# FSS0_FSAS_OTFA_REGS_0FC20000h register map
Vendor: Texas Instruments
Peripheral module from a debugger description file (folder AM275x).
Registers are 32-bit, read-write, reset 0x0 unless marked. A register's access mark holds for its fields unless they carry their own. Offsets are as the file gives them; lines under a group give offsets from that group; [hi:lo] are bit positions; {n}, {i} and the like mark numbered series; 'fields as' and 'values as' point back to an identical list; <NAME> marks a mode.

## fsas_otfa_regs
0x00 FSAS_OTFA_REGS_REVID ro reset 0x47500101 — Revision
  [31:0] REVID — REVID Reset Source: rst_modg_rst_n
0x04 FSAS_OTFA_REGS_SCFG reset 0x2 — SysConfig
  [1:0] IDLE_MODE — IDLE MODE Reset Source: rst_modg_rst_n
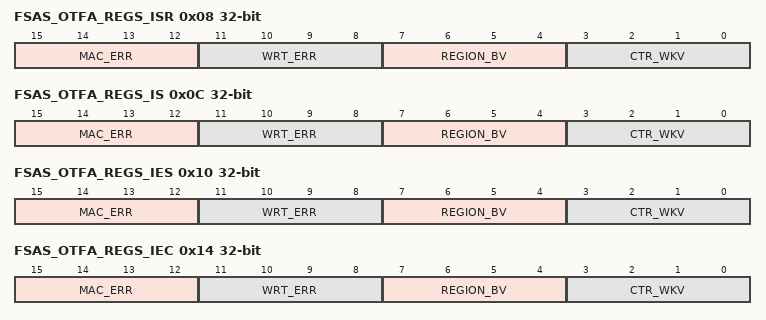
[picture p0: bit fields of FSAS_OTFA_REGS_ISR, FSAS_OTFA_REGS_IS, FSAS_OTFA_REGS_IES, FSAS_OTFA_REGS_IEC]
0x08 FSAS_OTFA_REGS_ISR — IRQSTATUS_RAW
  [15:12] MAC_ERR — MAC error Reset Source: rst_modg_rst_n
  [11:8] WRT_ERR — Write error Reset Source: rst_modg_rst_n
  [7:4] REGION_BV — Region overflow boundary event caused by a burst transaction crossed a start or end of a region Reset Source: rst_modg_rst_n
  [3:0] CTR_WKV — AES mode 0 enabled region violated Wrt Once Per Wrt Key rule Reset Source: rst_modg_rst_n
0x0C FSAS_OTFA_REGS_IS — IRQSTATUS
  fields as FSAS_OTFA_REGS_ISR
0x10 FSAS_OTFA_REGS_IES — IRQENABLE_SET
  fields as FSAS_OTFA_REGS_ISR
0x14 FSAS_OTFA_REGS_IEC — IRQENABLE_CLR
  fields as FSAS_OTFA_REGS_ISR
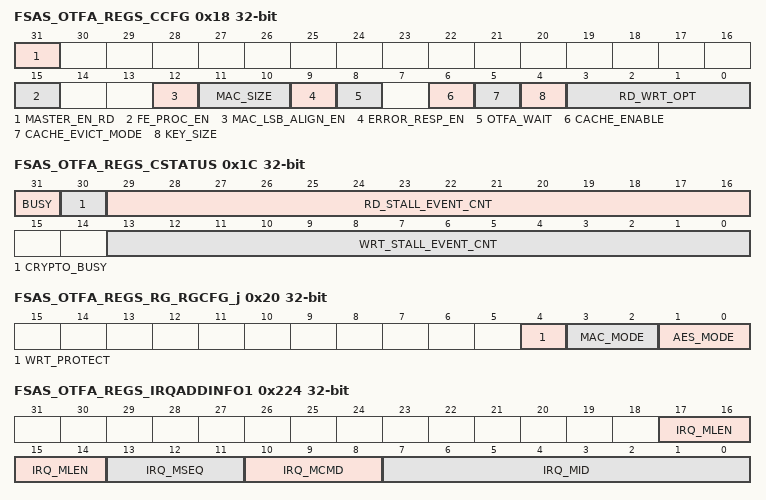
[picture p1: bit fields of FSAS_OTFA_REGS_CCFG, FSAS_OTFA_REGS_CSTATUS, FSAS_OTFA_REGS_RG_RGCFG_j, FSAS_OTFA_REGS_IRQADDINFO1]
0x18 FSAS_OTFA_REGS_CCFG — CryptoCfg
  [31] MASTER_EN_RD — This register controls the enabling the functionality of this IP Disabled and Bypass mode active Reset Source: rst_modg_rst_n
  [15] FE_PROC_EN — Setting this register to 1'b1 enables performance enhancement that performs AES computations on command rather than read return. Reset Source: rst_modg_rst_n
  [12] MAC_LSB_ALIGN_EN — This register is used to enable MAC to be always lsb aligned. For legacy behavior with 4-byte MAC, this register can be retained at 1'b0. However for MAC sizes 8 through 16-bytes, only 1'b1 is supported for this register. Retaining this register at 1'b0 for MAC sizes 8 through 16-bytes results in undefined behavior. Reset Source: rst_modg_rst_n
  [11:10] MAC_SIZE — This register defines the MAC size. 2'b00: 4-bytes, 2'b01: 8-bytes, 2'b10: 12-bytes, 2'b11: 16-bytes. Reset Source: rst_modg_rst_n
  [9] ERROR_RESP_EN — This register controls the enabling the the ocp error response for mac errors Reset Source: rst_modg_rst_n
  [8] OTFA_WAIT — This register allows the ability to stop accepting any new transactions from getting accepted and allow the current transactions to complete Reset Source: rst_modg_rst_n
  [6] CACHE_ENABLE — MAC cache enable Reset Source: rst_modg_rst_n
  [5] CACHE_EVICT_MODE — cache evict mode Reset Source: rst_modg_rst_n
  [4] KEY_SIZE — Key Size, 0 128 Bit 1 256 Bit Reset Source: rst_modg_rst_n
  [3:0] RD_WRT_OPT — This register defines the static allocation of the AES cores to read transactions. The remainder will be allocated to write transactions Reset Source: rst_modg_rst_n
0x1C FSAS_OTFA_REGS_CSTATUS access not given — CryptoStatus
  [31] BUSY ro — 0 No transactions are active, crypto or none crypto 1 One or more transactions are active, crypto or none crypto Reset Source: rst_modg_rst_n
  [30] CRYPTO_BUSY ro — 0 No transactions are active, crypto or none crypto 1 One or more transactions are active, crypto or none crypto Reset Source: rst_modg_rst_n
  [29:16] RD_STALL_EVENT_CNT — rd stall event do to lack of eng Reset Source: rst_modg_rst_n (access R/W1TC)
  [13:0] WRT_STALL_EVENT_CNT — wrt stall event do to lack of eng Reset Source: rst_modg_rst_n (access R/W1TC)
0x20 FSAS_OTFA_REGS_RG_RGCFG_j — RegionCfg
  [4] WRT_PROTECT — WRT protect Reset Source: rst_modg_rst_n
  [3:2] MAC_MODE — MAC mode Reset Source: rst_modg_rst_n
  [1:0] AES_MODE — AES mode Reset Source: rst_modg_rst_n
0x24 FSAS_OTFA_REGS_RG_RGMACST_j — RegionMacStart
  [19:0] M_START — This defines the start of the mac buffer in 4KBytes steps Reset Source: rst_modg_rst_n
0x28 FSAS_OTFA_REGS_RG_RGST_j — RegionStart
  [19:0] R_START — This defines the start of the crypto region in 4KBytes steps Reset Source: rst_modg_rst_n
0x2C FSAS_OTFA_REGS_RG_RGSI_j — RegionSize
  [19:0] R_SIZE — This defines the size of the crypto region in 4KBytes steps Reset Source: rst_modg_rst_n
0x30 FSAS_OTFA_REGS_RG_RKEYE_j_k — RegionKeyE
  [31:0] R_KEY_E — Key E Reset Source: rst_modg_rst_n
0x50 FSAS_OTFA_REGS_RG_RKEYEP_j_k — RegionKeyEP
  [31:0] R_KEY_EP — Key EP Reset Source: rst_modg_rst_n
0x70 FSAS_OTFA_REGS_RG_RKEYA_j_k — RegionKeyA
  [31:0] R_KEY_A — Key A Reset Source: rst_modg_rst_n
0x80 FSAS_OTFA_REGS_RG_RKEYAP_j_k — RegionKeyAP
  [31:0] R_KEY_AP — Key AP Reset Source: rst_modg_rst_n
0x90 FSAS_OTFA_REGS_RG_RIV_j_k — RegionIV
  [31:0] R_IV — IV Reset Source: rst_modg_rst_n
0x220 FSAS_OTFA_REGS_IRQADDINFO0 ro — IRQAdditionalInfo0
  [31:0] IRQ_MADDR — Initiator Address which caused the event Reset Source: rst_modg_rst_n
0x224 FSAS_OTFA_REGS_IRQADDINFO1 ro — IRQAdditionalInfo1
  [17:14] IRQ_MLEN — Initiator LENGTH which caused the event Reset Source: rst_modg_rst_n
  [13:11] IRQ_MSEQ — Initiator SEQ which caused the event Reset Source: rst_modg_rst_n
  [10:8] IRQ_MCMD — Initiator CMD which caused the event Reset Source: rst_modg_rst_n
  [7:0] IRQ_MID — Initiator TAG ID which caused the event Reset Source: rst_modg_rst_n
0x228 FSAS_OTFA_REGS_MACCACHEINFO ro — MACCacheInfo
  [15:0] CACHE_MISS_EVENT_CNT — MAC Cache Miss event cnt Reset Source: rst_modg_rst_n
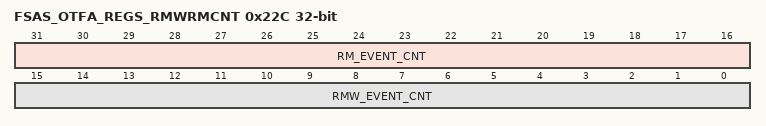
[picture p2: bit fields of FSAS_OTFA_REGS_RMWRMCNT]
0x22C FSAS_OTFA_REGS_RMWRMCNT ro — RMWRMCnt
  [31:16] RM_EVENT_CNT — RM event cnt Reset Source: rst_modg_rst_n
  [15:0] RMW_EVENT_CNT — RMW event cnt Reset Source: rst_modg_rst_n
